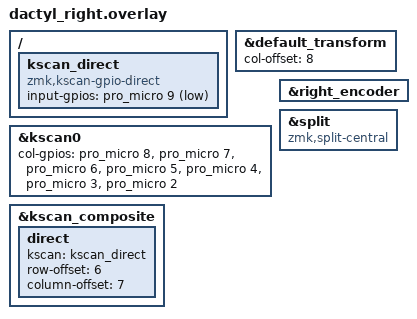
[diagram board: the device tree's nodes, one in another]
#include "dactyl.dtsi"

&default_transform {
    col-offset = <8>;
};

&kscan0 {
    col-gpios
        = <&pro_micro 8 GPIO_ACTIVE_HIGH>  // col0
        , <&pro_micro 7 GPIO_ACTIVE_HIGH>  // col1
        , <&pro_micro 6 GPIO_ACTIVE_HIGH>  // col2
        , <&pro_micro 5 GPIO_ACTIVE_HIGH>  // col3
        , <&pro_micro 4 GPIO_ACTIVE_HIGH>  // col4
        , <&pro_micro 3 GPIO_ACTIVE_HIGH>  // col5
        , <&pro_micro 2 GPIO_ACTIVE_HIGH>  // col6
        ;
};

/ {
    // Direct kscan for the EC11 push button on pin 9
    kscan_direct: kscan_direct {
        compatible = "zmk,kscan-gpio-direct";
        input-gpios = <&pro_micro 9 (GPIO_ACTIVE_LOW | GPIO_PULL_UP)>;
    };
};

// Add EC11 push button to the composite kscan
// Composite outputs (6,7), transform col-offset adds 8 -> RC(6,15)
&kscan_composite {
    direct {
        kscan = <&kscan_direct>;
        row-offset = <6>;
        column-offset = <7>;
    };
};

&right_encoder {
    status = "okay";
};

&split {
    compatible = "zmk,split-central";
    status = "okay";
};
